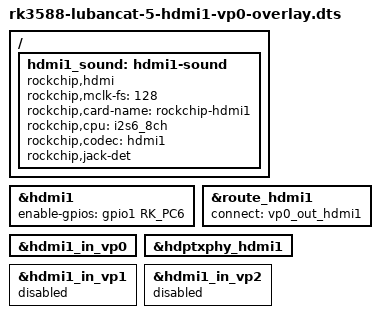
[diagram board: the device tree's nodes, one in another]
/dts-v1/;
/plugin/;

#include <dt-bindings/gpio/gpio.h>
#include <dt-bindings/pinctrl/rockchip.h>
#include <dt-bindings/display/drm_mipi_dsi.h>
#include <dt-bindings/interrupt-controller/irq.h>

/ {
	fragment@0 {
		target = <&hdmi1>;

		__overlay__ {
			enable-gpios = <&gpio1 RK_PC6 GPIO_ACTIVE_HIGH>;
			status = "okay";
		};
	};

	fragment@1 {
		target = <&route_hdmi1>;

		__overlay__ {
			status = "okay";
			connect = <&vp0_out_hdmi1>;
		};
	};

	fragment@2 {
		target = <&hdmi1_in_vp0>;

		__overlay__ {
			status = "okay";
		};
	};

	fragment@3 {
		target = <&hdptxphy_hdmi1>;

		__overlay__ {
			status = "okay";
		};
	};

	fragment@4 {
		target = <&hdmi1_in_vp1>;

		__overlay__ {
			status = "disabled";
		};
	};

	fragment@5 {
		target = <&hdmi1_in_vp2>;

		__overlay__ {
			status = "disabled";
		};
	};

	fragment@6 {
		target-path = "/";

		__overlay__ {
			hdmi1_sound: hdmi1-sound {
				status = "okay";
				compatible = "rockchip,hdmi";
				rockchip,mclk-fs = <128>;
				rockchip,card-name = "rockchip-hdmi1";
				rockchip,cpu = <&i2s6_8ch>;
				rockchip,codec = <&hdmi1>;
				rockchip,jack-det;
			};
		};
	};
};

